# MKE14D7 register map
File version: 1.6
Registers are 32-bit, read-write, reset 0x0 unless marked. A register's access mark holds for its fields unless they carry their own. Offsets are from the block's base; [hi:lo] are bit positions; {n}, {i} and the like mark numbered series; 'fields as' and 'values as' point back to an identical list.

## IEVENT — Intelligent event controller
Base 0x40019000; register names take the prefix IEVENT_
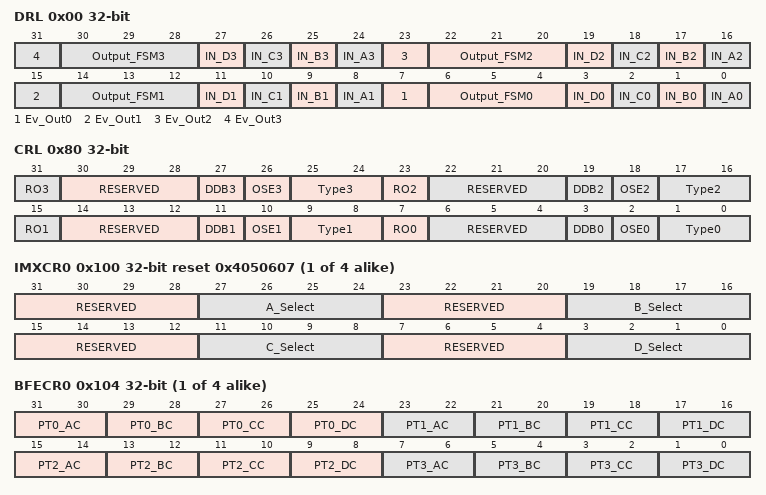
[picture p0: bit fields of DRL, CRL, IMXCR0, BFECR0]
0x00 DRL — iEvent Data Register: Low
  [8n+7] Ev_Out{n} (n=0..3) — Event Output {n}
    0=The event output is negated; 1=The event output is asserted
  [8n+6:8n+4] Output_FSM{n} ro (n=0..3) — Output Finite State Machine {n}
    0=The channel is disabled; FSM = idle; 1=The channel is enabled and waiting for the programmed event to occur; FSM = wfevt; 3=The programmed event has occurred and the channel is asserting its output; FSM = assert; 4=The channel is programmed for one-shot operation and the event has completed; FSM = os_hold; 5=The channel is waiting for the selected input signals to be negated before rearming; FSM = wfclr; 7=The event output has been acknowledged; done signals are broadcast during 1-cycle state; FSM = done
  [27] IN_D3 ro — Event Inputs {D3}
    0=The state of the event input was negated; 1=The state of the event input was asserted
  [26] IN_C3 ro — Event Inputs {C3}
    values as IN_D3
  [25] IN_B3 ro — Event Inputs {B3}
    values as IN_D3
  [24] IN_A3 ro — Event Inputs {A3}
    values as IN_D3
  [19] IN_D2 ro — Event Inputs {D2}
    values as IN_D3
  [18] IN_C2 ro — Event Inputs {C2}
    values as IN_D3
  [17] IN_B2 ro — Event Inputs {B2}
    values as IN_D3
  [16] IN_A2 ro — Event Inputs {A2}
    values as IN_D3
  [11] IN_D1 ro — Event Inputs {D1}
    values as IN_D3
  [10] IN_C1 ro — Event Inputs {C1}
    values as IN_D3
  [9] IN_B1 ro — Event Inputs {B1}
    values as IN_D3
  [8] IN_A1 ro — Event Inputs {A1}
    0=The state of the event input was negated
  [3] IN_D0 ro — Event Inputs {D0}
    values as IN_D3
  [2] IN_C0 ro — Event Inputs {C0}
    values as IN_D3
  [1] IN_B0 ro — Event Inputs {B0}
    values as IN_D3
  [0] IN_A0 ro — Event Inputs {A0}
    values as IN_D3
0x80 CRL — iEvent Control Register: Low
  [8n+7] RO{n} (n=0..3) — Read-Only {n}
    0=The iEvent configuration registers for this channel can be read and written; 1=The iEvent configuration registers for this channel can only be read
  [30:28] RESERVED ro
  [8n+3] DDB{n} (n=0..3) — Disable Done Broadcast {n}
    0=The event done indicators are broadcast to the appropriate selected event inputs; 1=The event done indicators are not broadcast to the appropriate selected event inputs
  [8n+2] OSE{n} (n=0..3) — One-Shot Enable {n}
    0=The channel event output is enabled to occur multiple times; 1=The channel event output is enabled to occur one time
  [8n+1:8n] Type{n} (n=0..3) — Output Channel Type {n}
    0=The channel is disabled; 1=The channel is defined as a DMA request output; 2=The channel is defined as a hardware trigger output; 3=The channel is defined as an interrupt request output
  [22:20] RESERVED ro
  [14:12] RESERVED ro
  [6:4] RESERVED ro
{0x100+8i} IMXCR{i} (i=0..3) ro reset 0x4050607 — iEvent Input Mux Configuration Register
  [31:28] RESERVED
  [27:24] A_Select
    {v}=Select input[{v}] as A (v=0..15)
  [23:20] RESERVED
  [19:16] B_Select
    {v}=Select input[{v}] as B (v=0..15)
  [15:12] RESERVED
  [11:8] C_Select
    {v}=Select input[{v}] as C (v=0..15)
  [7:4] RESERVED
  [3:0] D_Select
    {v}=Select input[{v}] as D (v=0..15)
{0x104+8i} BFECR{i} (i=0..3) — iEvent Boolean Function Eva1ation Configuration Register
  [31-8n:30-8n] PT{n}_AC (n=0..3) — Product Term {n}, A input Configuration
    0=Force the A input in this product term to a logical zero; 1=Pass the A input in this product term; 2=Complement the A input in this product term; 3=Force the A input in this product term to a logical one
  [29-8n:28-8n] PT{n}_BC (n=0..3) — Product Term {n}, B input Configuration
    0=Force the B input in this product term to a logical zero; 1=Pass the B input in this product term; 2=Complement the B input in this product term; 3=Force the B input in this product term to a logical one
  [27-8n:26-8n] PT{n}_CC (n=0..3) — Product Term {n}, C input Configuration
    0=Force the C input in this product term to a logical zero; 1=Pass the C input in this product term; 2=Complement the C input in this product term; 3=Force the C input in this product term to a logical one
  [25-8n:24-8n] PT{n}_DC (n=0..3) — Product Term {n}, D input Configuration
    0=Force the D input in this product term to a logical zero; 1=Pass the D input in this product term; 2=Complement the D input in this product term; 3=Force the D input in this product term to a logical one
